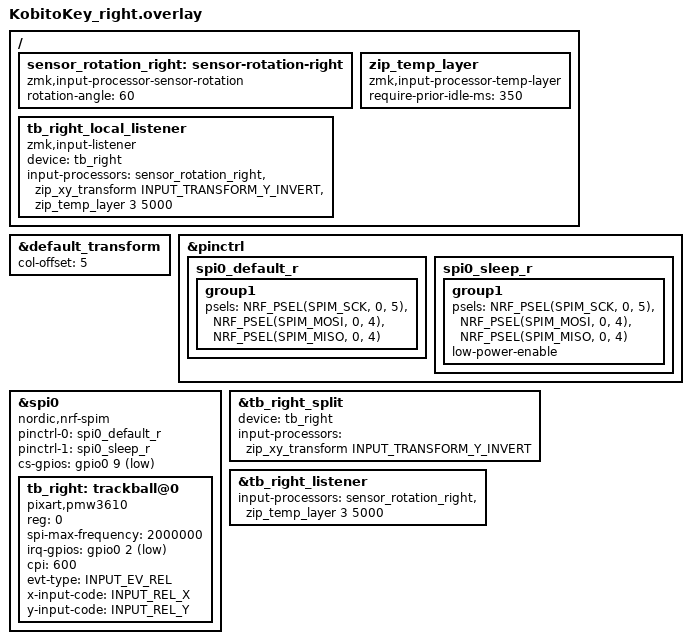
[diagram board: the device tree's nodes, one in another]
#include <zephyr/dt-bindings/pinctrl/nrf-pinctrl.h>
#include "kobitokey.dtsi"
#include <input/processors.dtsi>
#include <input/processors/sensor_rotation.dtsi>

/* 列オフセット */
&default_transform { col-offset = <5>; };

&pinctrl {
    spi0_default_r: spi0_default_r { group1 {
        psels = <NRF_PSEL(SPIM_SCK,  0, 5)>,
                <NRF_PSEL(SPIM_MOSI, 0, 4)>,
                <NRF_PSEL(SPIM_MISO, 0, 4)>;
    }; };
    spi0_sleep_r: spi0_sleep_r { group1 {
        psels = <NRF_PSEL(SPIM_SCK,  0, 5)>,
                <NRF_PSEL(SPIM_MOSI, 0, 4)>,
                <NRF_PSEL(SPIM_MISO, 0, 4)>;
        low-power-enable;
    }; };
};

&spi0 {
    status = "okay";
    compatible = "nordic,nrf-spim";
    pinctrl-0 = <&spi0_default_r>;
    pinctrl-1 = <&spi0_sleep_r>;
    pinctrl-names = "default", "sleep";
    cs-gpios = <&gpio0 9 GPIO_ACTIVE_LOW>;

    tb_right: trackball@0 {
        status = "okay";
        compatible = "pixart,pmw3610";
        reg = <0>;
        spi-max-frequency = <2000000>;
        irq-gpios = <&gpio0 2 (GPIO_ACTIVE_LOW | GPIO_PULL_UP)>;
        cpi = <600>;
        
        evt-type = <INPUT_EV_REL>;
        x-input-code = <INPUT_REL_X>;
        y-input-code = <INPUT_REL_Y>;
    };
};

&tb_right_split {
    device = <&tb_right>;

    input-processors = <&zip_xy_transform INPUT_TRANSFORM_Y_INVERT>;
};

/ {
    sensor_rotation_right: sensor-rotation-right {
        compatible = "zmk,input-processor-sensor-rotation";
        status = "okay";
        #input-processor-cells = <0>;
        rotation-angle = <60>;
    };
};

/ {
  /omit-if-no-ref/ zip_temp_layer: zip_temp_layer {
    compatible = "zmk,input-processor-temp-layer";
    #input-processor-cells = <2>;
    require-prior-idle-ms = <350>;
    status = "okay";
  };
};

&tb_right_listener {
    status = "okay";

    input-processors =
        <&sensor_rotation_right>,
        <&zip_temp_layer 3 5000>;
};

/ {
    tb_right_local_listener: tb_right_local_listener {
        compatible = "zmk,input-listener";
        status = "okay";
        device = <&tb_right>;

        input-processors =
            <&sensor_rotation_right>,
            <&zip_xy_transform INPUT_TRANSFORM_Y_INVERT>,
            <&zip_temp_layer 3 5000>;
    };
};
